# nrf9160_modem register map
Vendor: Nordic Semiconductor; Series: nrf91; File version: 1
CPU: CM4 r0p1, little endian, MPU, FPU, 3 interrupt priority bits
Registers are 32-bit, read-write, reset 0x0 unless marked. A register's access mark holds for its fields unless they carry their own. Offsets are from the block's base; [hi:lo] are bit positions; lines under a group give offsets from that group; {n}, {i} and the like mark numbered series; 'fields as' and 'values as' point back to an identical list.

## IPC_NS — Inter Processor Communication
Base 0x40053000
{0x0+4i} TASKS_SEND[{i}] (i=0..7) wo — Description collection: Trigger events on channel enabled in SEND_CNF[n].
  [0] TASKS_SEND — Trigger events on channel enabled in SEND_CNF[n].
    1=Trigger task
{0x100+4i} EVENTS_RECEIVE[{i}] (i=0..7) — Description collection: Event received on one or more of the enabled channels in RECEIVE_CNF[n].
  [0] EVENTS_RECEIVE — Event received on one or more of the enabled channels in RECEIVE_CNF[n].
    0=NotGenerated (Event not generated); 1=Generated (Event generated)
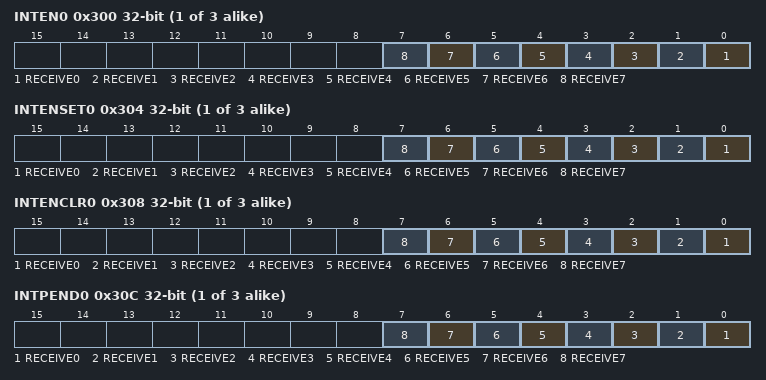
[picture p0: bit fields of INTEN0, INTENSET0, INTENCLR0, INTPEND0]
{0x300+0x10*i} INTEN{i} (i=0..2) — Enable or disable interrupt
  [all] fields
    0=Disabled; 1=Enabled
  [n] RECEIVE{n} (n=0..7) — Enable or disable interrupt for event RECEIVE[{n}]
{0x304+0x10*i} INTENSET{i} (i=0..2) — Enable interrupt
  [all] fields
    on read: 0=Disabled (Read: Disabled); 1=Enabled (Read: Enabled) | on write: 1=Set (Enable)
  [n] RECEIVE{n} (n=0..7) — Write '1' to enable interrupt for event RECEIVE[{n}]
{0x308+0x10*i} INTENCLR{i} (i=0..2) — Disable interrupt
  [all] fields
    on read: 0=Disabled (Read: Disabled); 1=Enabled (Read: Enabled) | on write: 1=Clear (Disable)
  [n] RECEIVE{n} (n=0..7) — Write '1' to disable interrupt for event RECEIVE[{n}]
{0x30C+0x10*i} INTPEND{i} ro (i=0..2) — Pending interrupts
  [all] fields
    on read: 0=NotPending (Read: Not pending); 1=Pending (Read: Pending)
  [n] RECEIVE{n} (n=0..7) — Read pending status of interrupt for event RECEIVE[{n}]
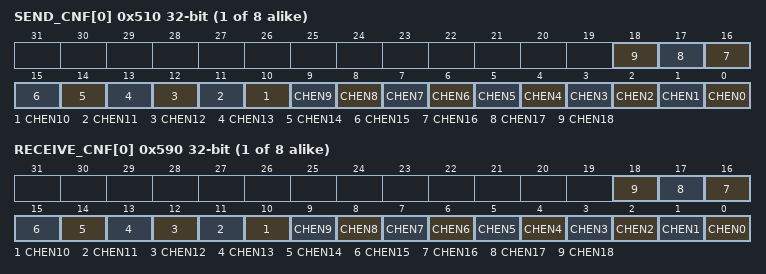
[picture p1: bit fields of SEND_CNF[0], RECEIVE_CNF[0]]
{0x510+4i} SEND_CNF[{i}] (i=0..7) — Description collection: Send event configuration for TASKS_SEND[n].
  [all] fields
    0=Disable broadcast; 1=Enable broadcast
  [n] CHEN{n} (n=0..18) — Enable broadcasting on channel {n}.
{0x590+4i} RECEIVE_CNF[{i}] (i=0..7) — Description collection: Receive event configuration for EVENTS_RECEIVE[n].
  [all] fields
    0=Disable events; 1=Enable events
  [n] CHEN{n} (n=0..18) — Enable subscription to channel {n}.
{0x610+4i} GPMEM[{i}] (i=0..1) — Description collection: General purpose memory.
  [31:0] GPMEM — General purpose memory

## ACL_NS — Access control lists
Base 0x40060000
{0x800+0x10*i} ACL[{i}] (i=0..7) group — Unspecified
  0x00 ADDR write-once — Description cluster: Configure the word-aligned start address of region n to protect
    [31:0] ADDR — Valid word-aligned start address of region n to protect. Address must point to a flash page boundary.
  0x04 SIZE write-once — Description cluster: Size of region to protect counting from address ACL[n].ADDR. Write '0' as no effect.
    [31:0] SIZE — Size of flash region n in bytes. Must be a multiple of the flash page size, and the maximum region size is limited to 512kB.
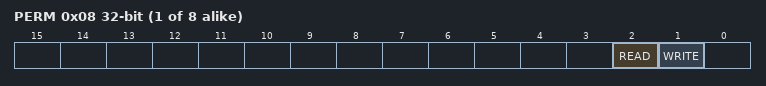
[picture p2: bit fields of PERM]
  0x08 PERM write-once — Description cluster: Access permissions for region n as defined by start address ACL[n].ADDR and size ACL[n].SIZE
    [2] READ — Configure read permissions for region n. Write '0' has no effect.
      0=Enable (Allow read instructions to region n); 1=Disable (Block read instructions to region n)
    [1] WRITE — Configure write and erase permissions for region n. Write '0' has no effect.
      0=Enable (Allow write and erase instructions to region n); 1=Disable (Block write and erase instructions to region n)

## KMU_NS — Key Management Unit
Base 0x40060000; alternate view of ACL_NS
0x00 TASKS_PUSH_KEYSLOT wo — Push a key slot over secure APB.
  [0] TASKS_PUSH_KEYSLOT
    1=Trigger task
0x100 EVENTS_KEYSLOT_PUSHED — Key successfully pushed over secure APB.
  [0] EVENTS_KEYSLOT_PUSHED
    0=NotGenerated (Event not generated); 1=Generated (Event generated)
0x104 EVENTS_KEYSLOT_REVOKED — Key has been revoked and cannot be tasked for selection.
  [0] EVENTS_KEYSLOT_REVOKED
    values as EVENTS_KEYSLOT_PUSHED.EVENTS_KEYSLOT_PUSHED
0x108 EVENTS_KEYSLOT_ERROR — No key slot selected or no destination address defined or error during push mechanism.
  [0] EVENTS_KEYSLOT_ERROR
    values as EVENTS_KEYSLOT_PUSHED.EVENTS_KEYSLOT_PUSHED
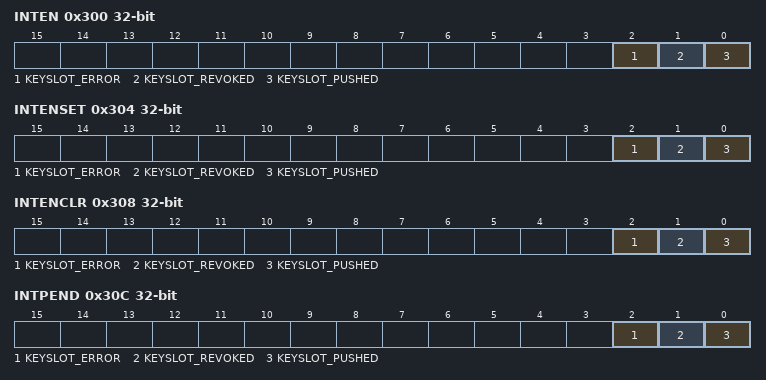
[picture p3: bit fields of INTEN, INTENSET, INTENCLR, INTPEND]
0x300 INTEN — Enable or disable interrupt
  [all] fields
    0=Disabled; 1=Enabled
  [2] KEYSLOT_ERROR — Enable or disable interrupt for event KEYSLOT_ERROR
  [1] KEYSLOT_REVOKED — Enable or disable interrupt for event KEYSLOT_REVOKED
  [0] KEYSLOT_PUSHED — Enable or disable interrupt for event KEYSLOT_PUSHED
0x304 INTENSET — Enable interrupt
  [all] fields
    on read: 0=Disabled (Read: Disabled); 1=Enabled (Read: Enabled) | on write: 1=Set (Enable)
  [2] KEYSLOT_ERROR — Write '1' to enable interrupt for event KEYSLOT_ERROR
  [1] KEYSLOT_REVOKED — Write '1' to enable interrupt for event KEYSLOT_REVOKED
  [0] KEYSLOT_PUSHED — Write '1' to enable interrupt for event KEYSLOT_PUSHED
0x308 INTENCLR — Disable interrupt
  [all] fields
    on read: 0=Disabled (Read: Disabled); 1=Enabled (Read: Enabled) | on write: 1=Clear (Disable)
  [2] KEYSLOT_ERROR — Write '1' to disable interrupt for event KEYSLOT_ERROR
  [1] KEYSLOT_REVOKED — Write '1' to disable interrupt for event KEYSLOT_REVOKED
  [0] KEYSLOT_PUSHED — Write '1' to disable interrupt for event KEYSLOT_PUSHED
0x30C INTPEND ro — Pending interrupts
  [all] fields
    on read: 0=NotPending (Read: Not pending); 1=Pending (Read: Pending)
  [2] KEYSLOT_ERROR — Read pending status of interrupt for event KEYSLOT_ERROR
  [1] KEYSLOT_REVOKED — Read pending status of interrupt for event KEYSLOT_REVOKED
  [0] KEYSLOT_PUSHED — Read pending status of interrupt for event KEYSLOT_PUSHED
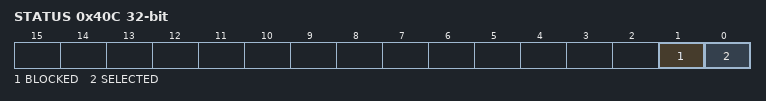
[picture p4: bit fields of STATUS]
0x40C STATUS ro — Status bits for KMU operation.
  [1] BLOCKED — Violation status
    0=Disabled (No access violation detected.); 1=Enabled (Access violation detected and blocked.)
  [0] SELECTED — Key slot ID successfully selected by the KMU.
    0=Disabled (No key slot ID selected by KMU); 1=Enabled (Key slot ID successfully selected by KMU)
0x500 SELECTKEYSLOT — Select key slot ID to be read over AHB or pushed over secure APB when TASKS_PUSH_KEYSLOT is started.
  [7:0] ID
